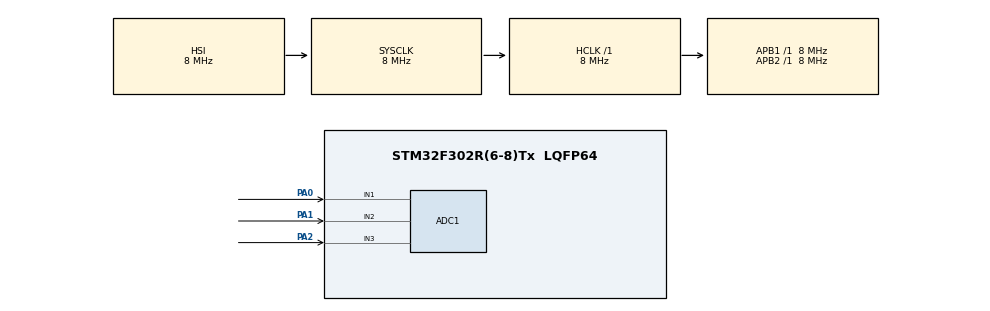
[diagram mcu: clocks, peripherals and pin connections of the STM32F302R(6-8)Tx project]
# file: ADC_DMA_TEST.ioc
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ADC1.Channel-0\#ChannelRegularConversion=ADC_CHANNEL_1
ADC1.Channel-1\#ChannelRegularConversion=ADC_CHANNEL_2
ADC1.Channel-2\#ChannelRegularConversion=ADC_CHANNEL_3
ADC1.ContinuousConvMode=ENABLE
ADC1.NbrOfConversion=3
ADC1.NbrOfConversionFlag=1
ADC1.Offset-0\#ChannelRegularConversion=0
ADC1.Offset-1\#ChannelRegularConversion=0
ADC1.Offset-2\#ChannelRegularConversion=0
ADC1.OffsetNumber-0\#ChannelRegularConversion=ADC_OFFSET_NONE
ADC1.OffsetNumber-1\#ChannelRegularConversion=ADC_OFFSET_NONE
ADC1.OffsetNumber-2\#ChannelRegularConversion=ADC_OFFSET_NONE
ADC1.Rank-0\#ChannelRegularConversion=1
ADC1.Rank-1\#ChannelRegularConversion=2
ADC1.Rank-2\#ChannelRegularConversion=3
ADC1.SamplingTime-0\#ChannelRegularConversion=ADC_SAMPLETIME_61CYCLES_5
ADC1.SamplingTime-1\#ChannelRegularConversion=ADC_SAMPLETIME_61CYCLES_5
ADC1.SamplingTime-2\#ChannelRegularConversion=ADC_SAMPLETIME_61CYCLES_5
ADC1.SamplingTimeOPAMP-1\#ChannelRegularConversion=ADC_SAMPLETIME_4CYCLES_5
ADC1.SamplingTimeOPAMP-2\#ChannelRegularConversion=ADC_SAMPLETIME_4CYCLES_5
ADC1.master=1
Dma.ADC1.0.Direction=DMA_PERIPH_TO_MEMORY
Dma.ADC1.0.Instance=DMA1_Channel1
Dma.ADC1.0.MemDataAlignment=DMA_MDATAALIGN_WORD
Dma.ADC1.0.MemInc=DMA_MINC_ENABLE
Dma.ADC1.0.Mode=DMA_CIRCULAR
Dma.ADC1.0.PeriphDataAlignment=DMA_PDATAALIGN_WORD
Dma.ADC1.0.PeriphInc=DMA_PINC_DISABLE
Dma.ADC1.0.Priority=DMA_PRIORITY_LOW
Dma.Request0=ADC1
Mcu.Family=STM32F3
Mcu.Name=STM32F302R(6-8)Tx
Mcu.Package=LQFP64
NVIC.DMA1_Channel1_IRQn=true\:0\:0\:false\:false\:true\:false\:true\:true
NVIC.PriorityGroup=NVIC_PRIORITYGROUP_4
PA0.Mode=IN1-Single-Ended
PA0.Signal=ADC1_IN1
PA1.Mode=IN2-Single-Ended
PA1.Signal=ADC1_IN2
PA13.Mode=Serial_Wire
PA13.Signal=SYS_JTMS-SWDIO
PA14.Mode=Serial_Wire
PA14.Signal=SYS_JTCK-SWCLK
PA2.Mode=IN3-Single-Ended
PA2.Signal=ADC1_IN3
PF0-OSC_IN.Mode=HSE-External-Oscillator
PF0-OSC_IN.Signal=RCC_OSC_IN
PF1-OSC_OUT.Mode=HSE-External-Oscillator
PF1-OSC_OUT.Signal=RCC_OSC_OUT
ProjectManager.HeapSize=0x200
ProjectManager.StackSize=0x400
ProjectManager.TargetToolchain=STM32CubeIDE
RCC.AHBFreq_Value=8000000
RCC.APB1Freq_Value=8000000
RCC.APB2Freq_Value=8000000
RCC.CortexFreq_Value=8000000
RCC.HSE_VALUE=8000000
RCC.HSI_VALUE=8000000
RCC.LSE_VALUE=32768
RCC.SYSCLKFreq_VALUE=8000000
board=custom

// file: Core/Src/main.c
/* USER CODE BEGIN Header */
/**
  ******************************************************************************
  * @file           : main.c
  * @brief          : Main program body
  ******************************************************************************
  * @attention
  *
  * Copyright (c) 2025 STMicroelectronics.
  * All rights reserved.
  *
  * This software is licensed under terms that can be found in the LICENSE file
  * in the root directory of this software component.
  * If no LICENSE file comes with this software, it is provided AS-IS.
  *
  ******************************************************************************
  */
/* USER CODE END Header */
#include "main.h"

/* USER CODE BEGIN PD */
uint32_t adcValues[3];

uint32_t data1;
uint32_t data2;
uint32_t data3;

/* USER CODE END PD */

ADC_HandleTypeDef hadc1;

void SystemClock_Config(void);
static void MX_GPIO_Init(void);
static void MX_ADC1_Init(void);
/* USER CODE BEGIN PFP */
void HAL_ADC_ConvCpltCallback(ADC_HandleTypeDef* hadc)
{
   if(hadc->Instance == ADC1)
   {
       data1 = adcValues[0];
       data2 = adcValues[1];
       data3 = adcValues[2];
   }
}

/* USER CODE END PFP */

int main(void)
{

  /* MCU Configuration--------------------------------------------------------*/

  /* Reset of all peripherals, Initializes the Flash interface and the Systick. */
  HAL_Init();

  /* Configure the system clock */
  SystemClock_Config();

  /* Initialize all configured peripherals */
  MX_GPIO_Init();
  MX_ADC1_Init();

  /* USER CODE BEGIN 2 */
  HAL_ADC_Start_DMA(&hadc1, adcValues, 3);

  /* USER CODE END 2 */

  /* Infinite loop */
  while (1)
  {

  }
}

void SystemClock_Config(void)
{
  RCC_OscInitTypeDef RCC_OscInitStruct = {0};
  RCC_ClkInitTypeDef RCC_ClkInitStruct = {0};

  /** Initializes the RCC Oscillators according to the specified parameters
  * in the RCC_OscInitTypeDef structure.
  */
  RCC_OscInitStruct.OscillatorType = RCC_OSCILLATORTYPE_HSI;
  RCC_OscInitStruct.HSIState = RCC_HSI_ON;
  RCC_OscInitStruct.HSICalibrationValue = RCC_HSICALIBRATION_DEFAULT;
  RCC_OscInitStruct.PLL.PLLState = RCC_PLL_NONE;
  if (HAL_RCC_OscConfig(&RCC_OscInitStruct) != HAL_OK)
  {
    Error_Handler();
  }

  /** Initializes the CPU, AHB and APB buses clocks
  */
  RCC_ClkInitStruct.ClockType = RCC_CLOCKTYPE_HCLK|RCC_CLOCKTYPE_SYSCLK
                              |RCC_CLOCKTYPE_PCLK1|RCC_CLOCKTYPE_PCLK2;
  RCC_ClkInitStruct.SYSCLKSource = RCC_SYSCLKSOURCE_HSI;
  RCC_ClkInitStruct.AHBCLKDivider = RCC_SYSCLK_DIV1;
  RCC_ClkInitStruct.APB1CLKDivider = RCC_HCLK_DIV1;
  RCC_ClkInitStruct.APB2CLKDivider = RCC_HCLK_DIV1;

  if (HAL_RCC_ClockConfig(&RCC_ClkInitStruct, FLASH_LATENCY_0) != HAL_OK)
  {
    Error_Handler();
  }
}

void Error_Handler(void)
{
  __disable_irq();
  while (1)
  {
  }
}
